# PIC32CM6408PL10028 device description
Architecture: CORTEX-M0PLUS; Family: PIC32CMPL; Series: PIC32CMPL10
Registers are 32-bit, read-write, reset 0x0 unless marked. A register's access mark holds for its fields unless they carry their own. Offsets are from the block's base; [hi:lo] are bit positions; {n}, {i} and the like mark numbered series; 'fields as' and 'values as' point back to an identical list.

## MTB — Cortex-M0+ Micro-Trace Buffer
Instances: MTB 0x41008000
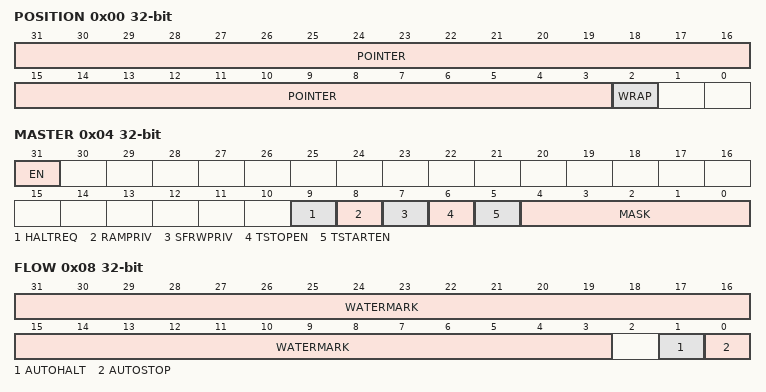
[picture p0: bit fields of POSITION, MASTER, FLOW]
0x00 POSITION reset not defined — MTB Position
  [31:3] POINTER — Trace Packet Location Pointer
  [2] WRAP — Pointer Value Wraps
0x04 MASTER — MTB Master
  [31] EN — Main Trace Enable
  [9] HALTREQ — Halt Request
  [8] RAMPRIV — SRAM Privilege
  [7] SFRWPRIV — Special Function Register Write Privilege
  [6] TSTOPEN — Trace Stop Input Enable
  [5] TSTARTEN — Trace Start Input Enable
  [4:0] MASK — Maximum Value of the Trace Buffer in SRAM
0x08 FLOW — MTB Flow
  [31:3] WATERMARK — Watermark value
  [1] AUTOHALT — Auto Halt Request
  [0] AUTOSTOP — Auto Stop Tracing
0x0C BASE ro reset not defined — MTB Base
0xF00 ITCTRL reset not defined — MTB Integration Mode Control
0xFA0 CLAIMSET reset not defined (atomic set) — MTB Claim Set
0xFA4 CLAIMCLR reset not defined (atomic clear) — MTB Claim Clear
0xFB0 LOCKACCESS reset not defined — MTB Lock Access
0xFB4 LOCKSTATUS ro reset not defined — MTB Lock Status
0xFB8 AUTHSTATUS ro reset not defined — MTB Authentication Status
0xFBC DEVARCH ro reset not defined — MTB Device Architecture
0xFC8 DEVID ro reset not defined — MTB Device Configuration
0xFCC DEVTYPE ro reset not defined — MTB Device Type
{0xFC0+4i} PID{i} ro reset not defined (i=4..7) — Peripheral Identification {i}
{0xFE0+4i} PID{i} ro reset not defined (i=0..3) — Peripheral Identification {i}
{0xFF0+4i} CID{i} ro reset not defined (i=0..3) — Component Identification {i}

## NVIC — Nested Vectored Interrupt Controller
Instances: NVIC 0xE000E100
0x00 ISER — Interrupt Set Enable Register
  [14:0] SETENA — Interrupt set enable bits
0x80 ICER — Interrupt Clear Enable Register
  [14:0] CLRENA — Interrupt clear-enable bits
0x100 ISPR — Interrupt Set Pending Register
  [14:0] SETPEND — Interrupt set-pending bits
0x180 ICPR — Interrupt Clear Pending Register
  [14:0] CLRPEND — Interrupt clear-pending bits
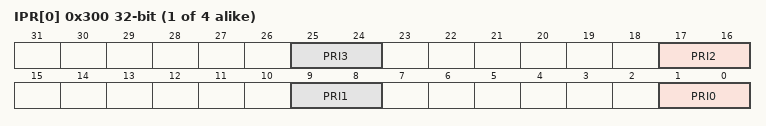
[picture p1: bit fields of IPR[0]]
{0x300+4i} IPR[{i}] (i=0..3) — Interrupt Priority Register n
  [8n+1:8n] PRI{n} (n=0..3) — Priority of interrupt n

## NVMCTRL — Non-Volatile Memory Controller
Instances: NVMCTRL 0x41004000
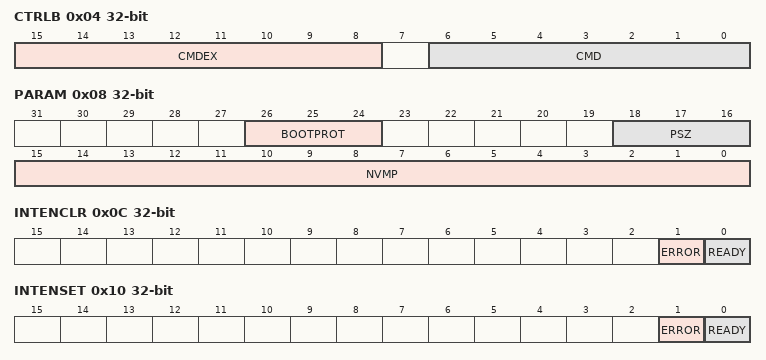
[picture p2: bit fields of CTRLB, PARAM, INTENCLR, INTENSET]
0x04 CTRLB — Control B
  [15:8] CMDEX — Command Execution
    165=KEY (Execution key)
  [6:0] CMD — Command
    0=NOCMD (No command); 1=NOOP (No operation); 2=FLWR (Flash Write Enable); 8=FLPER (Flash Page Erase Enable); 9=FLMPER2 (Flash 2-page Erase Enable); 10=FLMPER4 (Flash 4-page Erase Enable); 11=FLMPER8 (Flash 8-page Erase Enable); 12=FLMPER16 (Flash 16-page Erase Enable); 13=FLMPER32 (Flash 32-page Erase Enable); 14=LR (Lock Region. Sets the bit in the Region n Lock Bits bit field in the Lock Section register (NVMCTRL.LOCK) corresponding to the address location in the ADDR register.); 15=UR (Unlock Region. Clears the bit in NVMCTRL.LOCK corresponding to the address location in the ADDR register.); 16=EBOOTCFG (Erase BOOTCFG Page Enable); 17=WBOOTCFG (Write BOOTCFG Page Enable); 18=WLOCKREGION (Write Enable to ROMCFG.NVMLOCKREGION. Writes to other addresses will cause STATUS.PROGE to be set.); 32=WROMCFG (Write ROMCFG Page Enable. The ROMCFG Page is used by the boot ROM to store Debug Access Level (DAL) bits and other security or protection bits for such as CEHL and Immutable boot.); 33=CHER (Erase FlashRequires DAL == 2 or SYSINT privileges)
0x08 PARAM ro reset not defined — NVM Parameters
  [26:24] BOOTPROT — Boot Section Size
    0=SIZE_32768BYTES (32768 bytes are protected.); 1=SIZE_16384BYTES (16384 bytes are protected.); 2=SIZE_8192BYTES (8192 bytes are protected.); 3=SIZE_4096BYTES (4096 bytes are protected.); 4=SIZE_2048BYTES (2048 bytes are protected.); 5=SIZE_1024BYTES (1024 bytes are protected.); 6=SIZE_512BYTES (512 bytes are protected.); 7=SIZE_0BYTES (0 bytes are protected.)
  [18:16] PSZ — Page Size
    0=8 bytes; 1=16 bytes; 2=32 bytes; 3=64 bytes; 4=128 bytes; 5=256 bytes; 6=512 bytes; 7=1024 bytes
  [15:0] NVMP — NVM Parameters
0x0C INTENCLR (atomic clear) — Interrupt Enable Clear
  [1] ERROR — Error Interrupt Enable
  [0] READY — NVM Ready Interrupt Enable
0x10 INTENSET (atomic set) — Interrupt Enable Set
  fields as INTENCLR
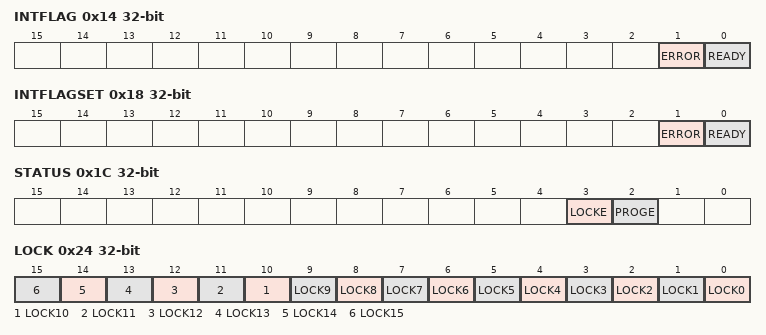
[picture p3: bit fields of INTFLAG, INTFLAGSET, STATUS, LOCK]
0x14 INTFLAG (atomic clear) — Interrupt Flag Status and Clear
  [1] ERROR
  [0] READY — NVM Ready
0x18 INTFLAGSET (atomic clear) — Interrupt Flag Software Set
  [1] ERROR
  [0] READY — NVM Ready
0x1C STATUS
  [3] LOCKE — Lock Error Status
  [2] PROGE — Programming Error Status
0x20 ADDR — Address
  [31:0] ADDR — NVM Address
0x24 LOCK ro reset not defined — Lock Section
  [n] LOCK{n} (n=0..15) — Region {n} Lock Bit
0x28 DATA ro reset not defined — Read Data
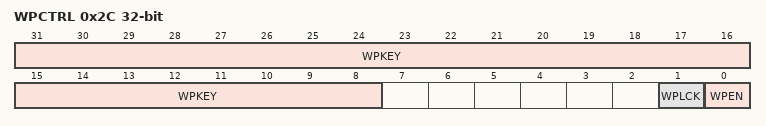
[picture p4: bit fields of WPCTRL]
0x2C WPCTRL — Write Protection Control
  [31:8] WPKEY — Write Protection Key
    0x4E564D=KEY (Allow writes to the WPCTRL register)
  [1] WPLCK — Write Protection Lock
  [0] WPEN — Write Protection Enable
